# icont5_cfg_targetdb register map
Vendor: Texas Instruments
Peripheral module from a debugger description file (folder iva2_arp32).
Address unit: 16 bits
Registers are 32-bit, read-write, reset 0x0 unless marked. A register's access mark holds for its fields unless they carry their own. Offsets are as the file gives them; lines under a group give offsets from that group; [hi:lo] are bit positions; {n}, {i} and the like mark numbered series; 'fields as' and 'values as' point back to an identical list; <NAME> marks a mode.

## DSS — ipxact12_to_ccs_generated
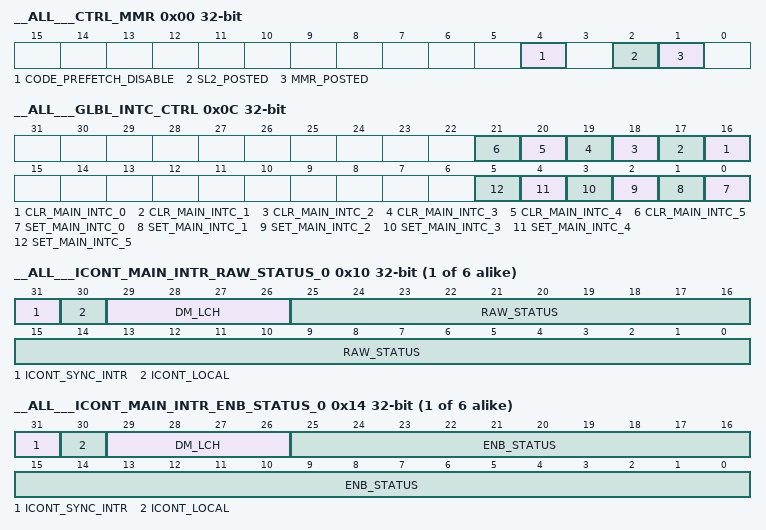
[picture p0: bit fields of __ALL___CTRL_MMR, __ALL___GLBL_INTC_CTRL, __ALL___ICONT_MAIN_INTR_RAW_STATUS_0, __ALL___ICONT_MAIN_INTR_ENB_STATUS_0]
0x00 __ALL___CTRL_MMR access per field
  [4] CODE_PREFETCH_DISABLE rw — Disable code prefetch from SL2 space.
  [2] SL2_POSTED rw — When set, SL2 posted writes from CPU will be enabled. When cleared, all SL2 writes from CPU are performed as non-posted writes (Write Queue will be disabled after completing the pending writes).
  [1] MMR_POSTED rw — When set, Posted MMR writes from CPU will be enabled. When cleared, all MMR writes from CPU are performed as non-posted writes.
0x0C __ALL___GLBL_INTC_CTRL — Global Interrupt controller enable register.
  [n+16] CLR_MAIN_INTC_{n} (n=0..5) — Write 1 to disable Main_{n} Interrupt controller.
  [n] SET_MAIN_INTC_{n} (n=0..5) — Write 1 to enable Main_{n} Interrupt controller. Read returns the Interrupt controllers enabled/disabled state.
{0x10+0x20*i} __ALL___ICONT_MAIN_INTR_RAW_STATUS_{i} access per field (i=0..5) — This provides the status of the ICONT Main interrupt sources, irrespective of enable bit. Write 1 to set the interrupt in Software (for test/debug).
  [31] ICONT_SYNC_INTR ro — ICONT Sync interrupt Source
  [30] ICONT_LOCAL ro — ICONT Local Interrupt Controller interrupt.
  [29:26] DM_LCH rw — Data Mover Logical Channel Data Transfer completion.
  [25:0] RAW_STATUS rw
{0x14+0x20*i} __ALL___ICONT_MAIN_INTR_ENB_STATUS_{i} access per field (i=0..5) — This provides the status of the ICONT Main interrupt sources enabled to interrupt. Write 1 to clear the interrupt in Software.
  [31] ICONT_SYNC_INTR ro — ICONT Sync interrupt Source
  [30] ICONT_LOCAL ro — ICONT Local Interrupt Controller interrupt.
  [29:26] DM_LCH rw — Data Mover Logical Channel Data Transfer completion.
  [25:0] ENB_STATUS rw
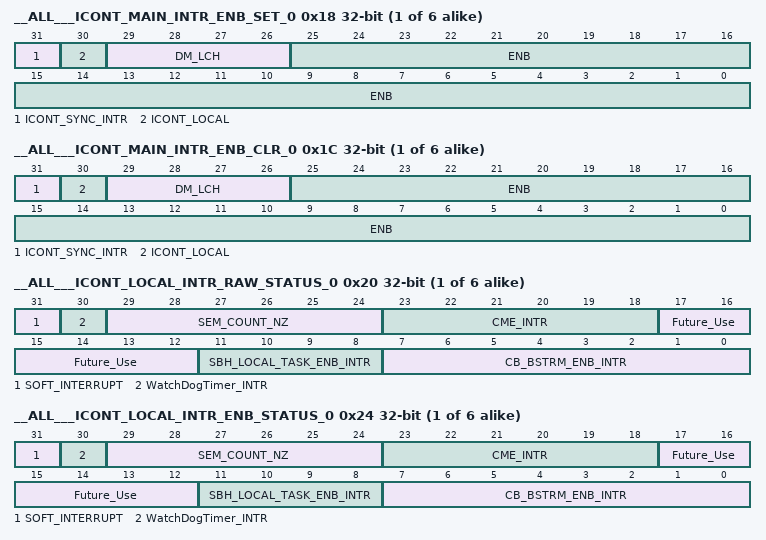
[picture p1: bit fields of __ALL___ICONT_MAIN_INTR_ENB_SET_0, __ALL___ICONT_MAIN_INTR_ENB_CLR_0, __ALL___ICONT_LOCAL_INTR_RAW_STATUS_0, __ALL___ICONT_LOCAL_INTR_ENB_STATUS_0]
{0x18+0x20*i} __ALL___ICONT_MAIN_INTR_ENB_SET_{i} (i=0..5) — Enables the corresponding interrupt source to generate interrupt. Write 1 to set the corresponding interrupt enable bit.
  [31] ICONT_SYNC_INTR — ICONT Sync interrupt Source
  [30] ICONT_LOCAL — ICONT Local Interrupt Controller interrupt.
  [29:26] DM_LCH — Data Mover Logical Channel Data Transfer completion.
  [25:0] ENB
{0x1C+0x20*i} __ALL___ICONT_MAIN_INTR_ENB_CLR_{i} (i=0..5) — Enables the corresponding interrupt source to generate interrupt. Write 1 to Clear the corresponding interrupt enable bit.
  fields as __ALL___ICONT_MAIN_INTR_ENB_SET_0
{0x20+0x20*i} __ALL___ICONT_LOCAL_INTR_RAW_STATUS_{i} (i=0..5) — This provides the status of the ICONT internal interrupt sources, irrespective of enable bit. Write 1 to set the interrupt in Software (for test/debug).
  [31] SOFT_INTERRUPT — Software Interrupt Source.
  [30] WatchDogTimer_INTR — WatchDog Timer interrupt.
  [29:24] SEM_COUNT_NZ — Interrupt source from the Semaphore counter. Refer Semaphore counter section for more details.
  [23:18] CME_INTR — CME Counter non-zero interrupt.
  [17:12] Future_Use — Reserved for Future use. Refer SL2BC section for more details.
  [11:8] SBH_LOCAL_TASK_ENB_INTR — Local SBH Task Notification
  [7:0] CB_BSTRM_ENB_INTR — BitStream Custom Block Interrupt Sources. 0 : Page_Done 1 : UnderRun 2 : Start_Code 3 : Store_Complete. 4 : Thress_Cross 5 : DDR_Empty 6 : Active to InActive transition. 7 : Start_Code_Overrun Refer Custom Block Bitstream section for details on its assertion & clearing.
{0x24+0x20*i} __ALL___ICONT_LOCAL_INTR_ENB_STATUS_{i} (i=0..5) — This provides the status of the ICONT internal interrupt sources enabled to interrupt. Write 1 to clear the interrupt in Software.
  fields as __ALL___ICONT_LOCAL_INTR_RAW_STATUS_0
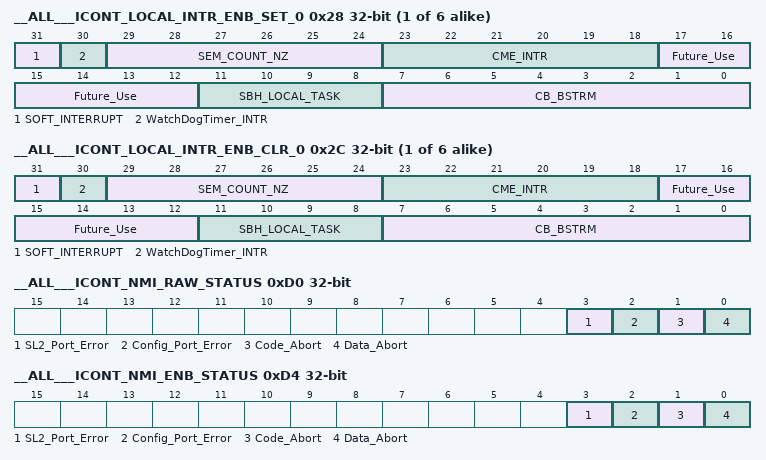
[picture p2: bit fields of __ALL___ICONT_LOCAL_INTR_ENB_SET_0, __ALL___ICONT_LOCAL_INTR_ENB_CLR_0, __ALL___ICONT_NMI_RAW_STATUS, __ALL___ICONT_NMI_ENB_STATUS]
{0x28+0x20*i} __ALL___ICONT_LOCAL_INTR_ENB_SET_{i} (i=0..5) — Enables the corresponding interrupt source to generate interrupt. Write 1 to set the corresponding interrupt enable bit.
  [31] SOFT_INTERRUPT — Enable Software Interrupt Source..
  [30] WatchDogTimer_INTR — WatchDog Timer interrupt.
  [29:24] SEM_COUNT_NZ — Interrupt source from the Semaphore counter.
  [23:18] CME_INTR — CME Counter non-zero interrupt.
  [17:12] Future_Use — Reserved for Future use. Refer SL2BC section for more details.
  [11:8] SBH_LOCAL_TASK — Enable Local SBH Task Notification.
  [7:0] CB_BSTRM — Enable BitStream Custom Block Interrupt Sources. 0 : Page_Done 1 : UnderRun 2 : Start_Code 3 : Store_Complete. 4 : Thress_Cross 5 : DDR_Empty 6 : Active to InActive transition. 7 : Start_Code_Overrun
{0x2C+0x20*i} __ALL___ICONT_LOCAL_INTR_ENB_CLR_{i} (i=0..5) — Enables the corresponding interrupt source to generate interrupt. Write 1 to Clear the corresponding interrupt enable bit.
  fields as __ALL___ICONT_LOCAL_INTR_ENB_SET_0
0xD0 __ALL___ICONT_NMI_RAW_STATUS access per field — This provides the status of the ICONT NMI sources, irrespective of enable bit. Write 1 to set the interrupt in Software (for test/debug).
  [3] SL2_Port_Error rw — Indicates error response on SL2 port.
  [2] Config_Port_Error rw — Indicates error response on Config master port.
  [1] Code_Abort rw — CPU Code access to Reserved space. NRP control register logs the access address.
  [0] Data_Abort rw — CPU data access to Reserved space. ICONT_NMI_ABORT_ADDR logs the access address.
0xD4 __ALL___ICONT_NMI_ENB_STATUS access per field — This provides the status of the ICONT NMI interrupt sources enabled to interrupt. Write 1 to clear the interrupt in Software.
  [3] SL2_Port_Error rw — Indicates error response on SL2 port.
  [2] Config_Port_Error rw — Indicates error response on Config master port.
  [1] Code_Abort rw — CPU code access to Reserved space. NRP control register logs the access address.
  [0] Data_Abort rw — CPU data access to Reserved space. ICONT_NMI_ABORT_ADDR logs the access address.
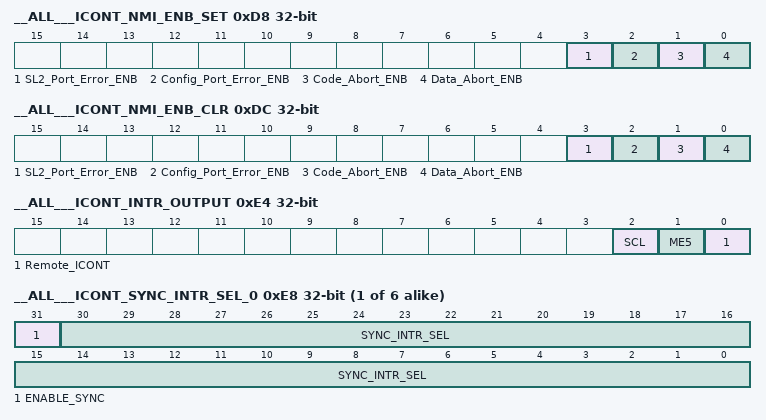
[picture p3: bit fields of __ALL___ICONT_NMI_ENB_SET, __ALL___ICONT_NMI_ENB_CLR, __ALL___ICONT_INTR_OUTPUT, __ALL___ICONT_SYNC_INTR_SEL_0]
0xD8 __ALL___ICONT_NMI_ENB_SET access per field — Enables the corresponding interrupt source to generate interrupt. Write 1 to set the corresponding interrupt enable bit.
  [3] SL2_Port_Error_ENB rw, [2] Config_Port_Error_ENB rw, [1] Code_Abort_ENB rw, [0] Data_Abort_ENB rw
0xDC __ALL___ICONT_NMI_ENB_CLR access per field — Enables the corresponding interrupt source to generate interrupt. Write 1 to Clear the corresponding interrupt enable bit.
  fields as __ALL___ICONT_NMI_ENB_SET
0xE0 __ALL___ICONT_NMI_ABORT_ADDR ro — Logs the Address that resulted in the CPU Data abort condition.
  [31:0] Address
0xE4 __ALL___ICONT_INTR_OUTPUT — Generates interrupt to remote ICONT, ME5, SCL modules. Corresponding bitfield is to be set to generate interrupt. The bitfield is selfcleared on generating interrupt.
  [2] SCL — Generates Interrupt to Scalar.
  [1] ME5 — Generates Interrupt to ME5.
  [0] Remote_ICONT — reserved.
{0xE8+4i} __ALL___ICONT_SYNC_INTR_SEL_{i} (i=0..5) — Selects the interrupt sources to be considered to generate the SYNC interrupt source
  [31] ENABLE_SYNC — When cleared to 0, blocks the SYNC interrupt generation. When set to 1, enables the SYNC interrupt to be generated.
  [30:0] SYNC_INTR_SEL
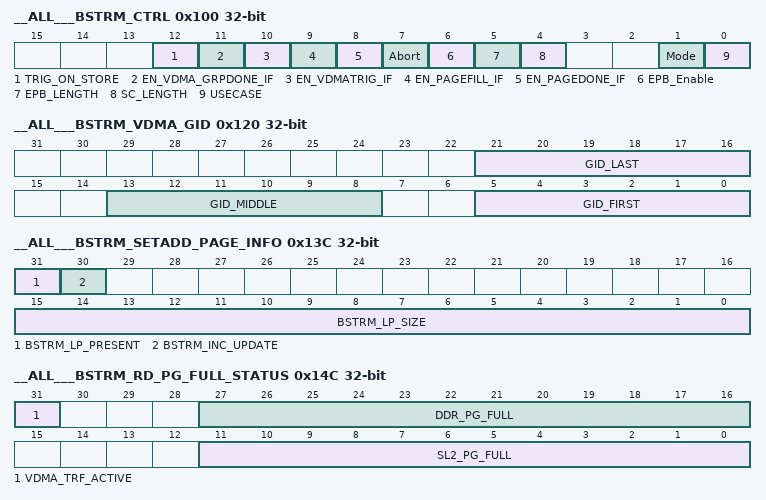
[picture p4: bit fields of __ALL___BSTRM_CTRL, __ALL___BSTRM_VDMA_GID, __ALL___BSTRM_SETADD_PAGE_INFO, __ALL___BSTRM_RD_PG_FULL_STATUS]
0x100 __ALL___BSTRM_CTRL access per field — This register is written by Software as part of configuration.
  [12] TRIG_ON_STORE rw — This is used in Encode usecase to specify if the BSTRM_STORE() CI should be considered as end of page, even when not completely filled. When 1, The BSTRM_STORE() CI should trigger all events that simillar to page fill on the last SL2 write. When 0, trigger is not generated on SL2 write completion.
  [11] EN_VDMA_GRPDONE_IF rw — Enables (when high) the VDMA to ICONT interface to communicate Page_Fill status. This should be enabled in Encode & in Slice level pipelining decode flow.
  [10] EN_VDMATRIG_IF rw — Enables (when high) the ICONT to VDMA Group Start trigger interface to communicate Page_Done status. This should be enabled in Encode & in Slice level pipelining decode flow.
  [9] EN_PAGEFILL_IF rw — Enables (when high) the ECD to ICONT interface to communicate Page_Fill status. This should be enabled in Sequential decode/encode flow.
  [8] EN_PAGEDONE_IF rw — Enables (when high) the ICONT to ECD interface to communicate Page_Done status. This should be enabled in Sequential decode/encode flow.
  [7] Abort rw — When asserted by software, forces the hardware to move to IDLE state (after completing the ongoing transfer). Writing 0 to this bit is ignored. This bit is auto cleared by HW.
  [6] EPB_Enable rw — Enables EPB byte detection & removal by hardware in Decoder Usecase. Enables EPB byte insertion by hardware in Encoder Usecase.
  [5] EPB_LENGTH rw — Specifies the length of the EPB pattern. 0 implies 3 Bytes pattern (lower bytes). 1 implies 4 Byte pattern.
  [4] SC_LENGTH rw — Specifies the length of the StartCode pattern. 0 implies 3 Bytes pattern (lower bytes). 1 implies 4 Byte pattern.
  [1] Mode rw — Used in Decoder usecase only. When set to 0, implies Typical flow where BitStream custom block and ECD HW block is used in sequential mode. When set to 1, implies Slice Level Pipeline mode where in BitStream custom block is used in parallel with ECD HW block.
  [0] USECASE rw — Indicates how the BitStream Custom Unit is being used. 0 indicates Decode usecase (default). 1 indicates Encode Usecase.
0x104 __ALL___BSTRM_SC_VAL reset 0x1 — This register is written by Software as part of configuration. This specifies the 32bit value that will be used as StartCode by Custom Unit.
  [31:0] SC_VAL — Start Code Pattern
0x108 __ALL___BSTRM_EPB_VAL reset 0x3 — This register is written by Software as part of configuration. In Decoder usecase, this specifies the 32 bit value that is detected as the Emulation Prevention Byte. The unit could be configured to automatically remove the least significant byte from the BitStream on detection. In Encoder usecase, this specifies the 32 bit value that is used along with BSTRM_EPB_MASK to detect when the EmulationPreventionByte is to be inserted. The unit could be configured to automatically insert the least significant byte of this register to the BitStream when needed.
  [31:0] EPB_VAL — For example, in Case of H-264 byte oriented stream, this value should be set to 0x000003.
0x10C __ALL___BSTRM_EPB_MASK reset 0xFFFFFFFC — This register is written by Software as part of configuration in Encoder usecase. This specifies the 32 bit mask value that will be used along with BSTRM_EPB_VAL in identifying Emulation Prevention Byte insertion.
  [31:0] EPB_MASK — Each bitfield enables the corresponding bitfield of BSTRM_EPB_VAL in Encoder usecase. For example, in Case of H-264 byte oriented stream, this value should be set to 0x00FFFFFC to detect 0x000001 and 0x000003 as condition needing EPB byte insertion.
0x110 __ALL___BSTRM_PAGE_SA — This register is written by Software as part of configuration. This specifies the starting address of the circular buffer in SL2 and is used to wrap around.
  [31:0] Start_Address — Starting address of the circular buffer. Address should be 128bit aligned and also aligned to the page size specified in BSTRM_PAGE_SIZE.
0x114 __ALL___BSTRM_PAGE_SIZE access per field — This register is written by Software as part of configuration. This specifies the size of each page in SL2. The value written is expected to be a one-hot value indicating the size in bytes. (For ex: 512Bytes = 0x200)
  [15:0] Page_Size rw — The value written is expected to be a one-hot value indicating the size in bytes. (For ex: 512Bytes = 0x200) Minimum supported size of page is 128bytes.
0x118 __ALL___BSTRM_PAGE_NUM access per field — This register is written by Software as part of configuration. This specifies the number of pages contained in the circular buffer.
  [15:0] Page_Num rw — Number of pages in the circular buffer
0x11C __ALL___BSTRM_THRESHOLD access per field — This is used in Decoder & Encoder usecase. In Decoder, This specifies the low watermark limit of the Valid data in SL2 buffer, below which the THRES_CROSS status bit need to be asserted by Custom Block. The contents of checked in the following sequence, work buffer, pre-fetch buffer, SL2 buffer. Note in case the EPB removal is enabled, the custom block would not know the EPB bytes in the portion that are in SL2. So, care is to be taken to account for this while programming this register. The value configured in this register should not exceed the page size. In Encode usecase, This specifies the low watermark limit of the free space in SL2 buffer, below which the THRES_CROSS status bit need to be asserted by Custom Block. Note in case the EPB removal is enabled, SW should include margin for EPB insertion while programming this register.
  [15:0] THRESHOLD rw — Decode usecase : Specifies the low-water mark of Valid Data in SL2 in terms of bytes. Encode usecase : Specifies the low-water mark of Free Space in SL2 in terms of bytes. This value should not exceed Page Size.
0x120 __ALL___BSTRM_VDMA_GID — Used when VDMA HW interface is enabled. This specifies the VDMA Group ID that should be used to trigger the VDMA transfers and to monitor the VDMA GroupDone.
  [21:16] GID_LAST — This VDMA GID is used when triggering the VDMA for the last page in Decode mode. Last page is assumed when BSTRM_LP_PRESENT bitfield is set to 1 and triggering for the last DDR PAGE. Not used in Encode usecase.
  [13:8] GID_MIDDLE — This VDMA GID is used when triggering the VDMA for the all pages except the first & last in Decoder mode. In Encode mode, This GID is used for all vdma transfers.
  [5:0] GID_FIRST — This VDMA GID is used when triggering the VDMA for the first page when _BSTRM_CONF CI is issued (with SL2 Filled Pages being 0*) in Decode mode. This value could be same as that of VDMA_GID_MIDDLE when the first page to be fetched is a full page. It could have a different GID value when the first page in DDR is partial and need to be bottom aligned in SL2 page. Note:* This GID will not be used if DDR page count equals 1 and Last Page is indicated. In this case, The first VDMA transfer will be triggerred with the GID_LAST ID. Not used in Encode usecase.
0x124 __ALL___BSTRM_SET_ADDR — Specifies the starting address (byte address) of the new BitStream in the SL2 page.
  [31:0] SET_ADDR
0x134 __ALL___BSTRM_SETADD_SL2_PG_FULL wo — BSTRM_SET_SL2_PG_FULL: (When Active bitfield in BSTRM_STAUS register is 0) In Decoder usecase in Typical flow (mode=0). Specifies the number of SL2 pages filled with BitStream data at the start of processing. In Encoder usecase, This specifies the number of SL2 pages that are empty at the start of processing. BSTRM_ADD_SL2_PG_FULL: (When Active bitfield in BSTRM_STAUS register is 1) In Decoder usecase, the subsequent SL2 page fills could be conveyed through SW by writing the incremental SL2 pages filled value. Note: This approach is used when HW interface is not used (ie., EN_VDMA_GRPDONE & EN_PAGEDONE bitfields are set to 0). In Encode usecase, Subsequent SL2 page availablity could be conveyed by SW by writing the incremental SL2 page value. Note: In both usecase, when used to convey incremental value, the HW will take the updated value when BSTRM_INC_UPDATE bitfield is set to 1.
  [11:0] SL2_PAGES — Specifies the amount of BitStream data available in DDR in terms of SL2 pages. All writes, done after initiating the BitStream custom unit, with non-zero value will be considered as additional page available. Used to generate VDMA triggers to fetch the data from DDR to SL2 when HW interface is enabled.
0x138 __ALL___BSTRM_SETADD_DDR_PAGES wo — Used in Decoder & Encoder usecase. BSTRM_SET_DDR_PAGES: (When Active bitfield in BSTRM_STATUS register is 0) This register is used to convey information related to BitStream Data in DDR that is yet to be copied to SL2 at the start of processing in Decoder usecase. This register is used to convey information related to pages available in DDR to store the encoded bitstream data in Encoder usecase. BSTRM_ADD_DDR_PAGES: (When Active bitfield in BSTRM_STATUS register is 1) When additional data is available in DDR after initiation in Decoder Fixed Chunk format (refer programming model section for details on Fixed Chunk format) or in encode usecase, the provided value is used to increment the earlier value. Note: When used to convey incremental value, the HW will take the updated value when BSTRM_INC_UPDATE bitfield is set to 1.
  [11:0] BSTRM_SETADD_DDR_PAGES — This is used in when HW interface is enabled to i) generate triggers on the VDMA HW interface (when enabled) on PageDone indication. ii) Determine if the current SL2 page is the last page (when Last_pg_present is set).
0x13C __ALL___BSTRM_SETADD_PAGE_INFO access per field — This is used to convey information regarding LastPage and its Size.
  [31] BSTRM_LP_PRESENT wo — This field is used in Decoder usecase only. This field indicates if the Last Page is present in SL2 or in DDR(When HW interface is used). This is always set in Frame or N-Nal format. In case of Fixed Chunk format, this depends on the BitStream data (refer Programming Model section for details on formats). This field is updated along with BSTRM_ADD_DDR_PAGES in Fixed Chunk format.
  [30] BSTRM_INC_UPDATE rw — This bitfield is used in both decode and encode usecase. This BSTRM_INC_UPDATE bitfield needs to be set to 1 to enable the Bitstream custom block to use the incremental value written in the following registers. 1) BSTRM_ADD_SL2_PG_FULL 2) BSTRM_ADD_DDR_PAGES 3) BSTRM_LP_SIZE 4) BSTRM_LP_PRESENT The BSTRM_INC_UPDATE bit will be autocleared to 0 on HW register update. After the HW registers are updated, BSTRM_SETADD_SL2_PG_FULL & BSTRM_SETADD_DDR_PAGES MMRs will be reset to zero (to ease subsequent incremental writes).
  [15:0] BSTRM_LP_SIZE rw — This field is used in Decoder usecase only. This specifies the size of the last page (in SL2). This register is written by Software as part of setup (using BSTRM_CONF() CI) or while updating when additional data chunks are available (SW update by setting BSTRM_INC_UPDATE=1). The value written is expected to be in terms of bytes. Note that the data need not be available in SL2 at the time of updating this register. When BSTRM_LP_PRESENT was already asserted during the previous update (either during setup or during incremental update), the new BSTRM_LP_SIZE value adds to the previous specified value.
0x140 __ALL___BSTRM_RD_ADDR ro — Returns the SL2 address pointing to the next bitstream data to be processed in Decoder usecase. Returns the SL2 address where the next bitstream byte is to be written in Encoder usecase. Note: Also refer LATCH_STATUS bit description.
  [31:0] RD_ADDR — SL2 address being processed in Decoder usecase. SL2 address to be written in Encoder usecase. Note that the BSTRM_RD_ADDR will not change after UNDERRUN/OVERFLOW status is set.
0x144 __ALL___BSTRM_RD_BITPTR ro — Returns the Bit pointer to be processed in Decoder usecase. Returns the current Bit Pointer within the Bitstream being encoded in encoder usecase. Note: Also refer LATCH_STATUS bit description.
  [2:0] RD_BitPtr — Note that the BSTRM_RD_BITPTR will not change after UNDERRUN/OVERFLOW status is set. Decoder usecase: Follows Big Endian notation. 0=>all 8 bits valid. Next bit to be read starting from bit[7] 1=>7 bits valid in byte starting from bit[6]. ... 7=>only 1 bit valid in the byte at position[0] Encoder usecase: 0=>Byte aligned. Next bit to be written at bit[7]. 1=>1bit present. Next bit to be written at bit[6]. ... 7=>7bits present. Next bit to be written at bit[0].
0x148 __ALL___BSTRM_RD_ZERO_BYTE_CNT ro — In decoder usecase: This register provides the count of zero bytes seen at the current Byte pointer. In Encoder usecase: This register provides the count of zero bytes encoded at the current byte pointer. Note: Also refer LATCH_STATUS bit description.
  [1:0] Zero_Byte_Count — Count of Zero bytes decoded/encoded at the current byte position. 0 : Byte pointer at end of non-zero byte position. 1 : Byte pointer has seen/encoded one zero-byte. 2 : Byte pointer has seen/encoded two zero-byte. 3 : Byte pointer has seen/encoded three or more zero-byte/s. Note: The contents of this register during Search of SC pattern or Non-Zero byte pattern (_BSTRM_Search_Bits CI) would be 1) Zero when the search ends sucessfully by detecting the pattern. 2) undefined when the search is aborted by SW or ends in an underrun condition.
0x14C __ALL___BSTRM_RD_PG_FULL_STATUS ro — In Decoder usecase. Returns the count of SL2 & DDR pages that contains BitStream data. (The count update of SL2 & DDR pages happens on the same cycle, thereby ensuring correct counts on all reads). In Encoder usecase. Returns the count of SL2 pages that are still empty. Note: Also refer LATCH_STATUS bit description.
  [31] VDMA_TRF_ACTIVE — Status bit indicating VDMA transfer trigerred by custom block (when VDMA hw interface is enabled) is ongoing.
  [27:16] DDR_PG_FULL — Used in SLice level Pipelining Flow only. Returns the count of DDR pages that contains (unread) BitStream data.
  [11:0] SL2_PG_FULL — Returns the count of SL2 pages that contains BitStream data (including the page being processed).
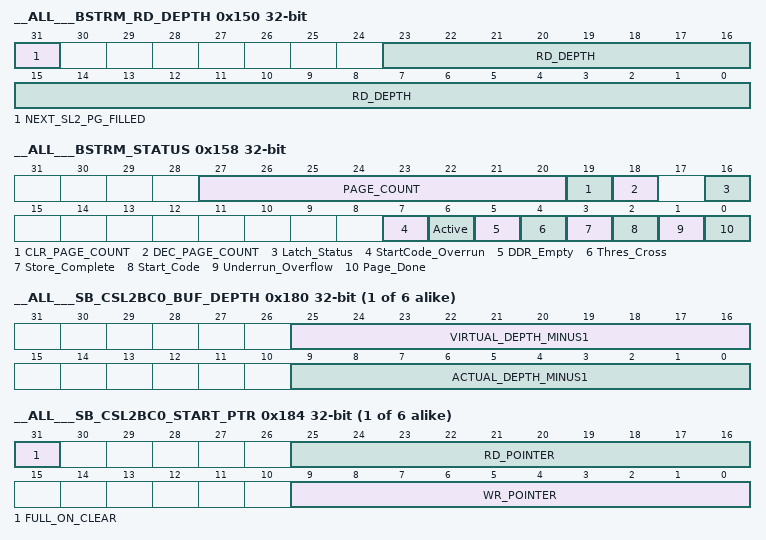
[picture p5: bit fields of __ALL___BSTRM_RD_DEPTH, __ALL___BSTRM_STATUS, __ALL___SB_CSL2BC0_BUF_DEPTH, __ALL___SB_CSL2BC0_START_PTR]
0x150 __ALL___BSTRM_RD_DEPTH ro — Returns the bytes yet to be read in the allocated SL2 pages in Decoder usecase. Returns the bytes yet to be filled in the allocated SL2 pages in Encoder usecase. (return value is ceiled to BSTRM_PAGE_SIZE) Note: Also refer LATCH_STATUS bit description.
  [31] NEXT_SL2_PG_FILLED — Decoder usecase: Indicates if the next SL2 page is filled with unread BitStream data (High) or is empty (Low=to be filled) Encoder usecase: Indicates if the more than 1 page is available for writing (when 1) or just one or no page is available(when 0).
  [23:0] RD_DEPTH — Returns the byte count. (Ceiled to BSTRM_PAGE_SIZE)
0x158 __ALL___BSTRM_STATUS access per field — Provides status of the custom block. Software writes 1 to the corresponding bitfield (except Thres_Cross & Active) to clear the events.
  [27:20] PAGE_COUNT ro — This bitfield is used in both Decode and Encode usecase. This bitfield is used in systems where the interrupt latency exceeds the custom block page processing time. When HW interface (either ECD or VDMA) is not enabled, this bitfield will be incremented by Custom Block on every page freed(in decode)/filled(in encode). SW would acknowledge this by decrementing (recommended) or clearing this bitfield. When VDMA HW interface is enabled, this bitfield is incremented on page freed/filled event that did not generate in VDMA trigger. This is possible when the VDMA is actively transferring data of last trigger or when the provided DDR_PAGES count has reached 0. For the former case, the custom block will decement this count when it triggers the next VDMA transfer. For latter, SW could either provide additional DDR pages to custom block OR could acknowledge its handling of "extra" page transfers by decrementing the count. This bitfield is not used when ECD HW interface is enabled. SW should update the PAGE_COUNT bitfield by writing 1 to the DEC_PAGE_COUNT or CLR_PAGE_COUNT bitfields. Writing 1 to DEC_PAGE_COUNT will decrement the PAGE_COUNT content by 1. Writing 1 to CLR_PAGE_COUNT will clear the PAGE_COUNT contents.
  [19] CLR_PAGE_COUNT rw — SW writes 1 to this bitfiles to clear the PAGE_COUNT bitfield to 0. This bit is auto cleared. (Note: The value will be updated in next cycle)
  [18] DEC_PAGE_COUNT rw — SW writes 1 to this bitfiles to decrement the PAGE_COUNT bitfield by 1. This bit is auto cleared. (Note: The value will be updated in next cycle)
  [16] Latch_Status rw — Used in both Encode & Decode Usecase. This bit has to be set to 1 to copy the current HW status registers into the memory mapped registers. This bit will be auto cleared to 0. Note: HW will implicitly assume Latch_Status condition when the Bitstream makes transition from ACTIVE to IDLE state. (ie., During Abort condition in Decoder usecase or Store_Complete condition in encode usecase). The following memory mapped register contents will be updated when this bit is set to 1. 1) BSTRM_RD_ADDR 2) BSTRM_RD_BITPTR 3) BSTRM_RD_ZERO_BYTE_CNT 4) BSTRM_RD_PG_FULL_STATUS 5) BSTRM_RD_PAGE_STATUS2 6) BSTRM_RD_DEPTH The above register will hold its contents untill LATCH_STATUS is set to 1 again.
  [7] StartCode_Overrun rw — This is used in Decoder usecase. This is asserted when StartCode is "parsed" as data using _BSTRM_READ*/FLUSH CIs. This bit is cleared by writing 1 to this bit.
  [6] Active ro — This indicates if the BitStream Custom Block is in active state (1) or in idle state (0). This bit is set by the _BSTRM_Conf intrinsic in both encode and decode usecase. This bit is cleared on the following condition i) Abort bitfield is set in BSTRM_CTRL register and on completion of active SL2 transaction. ii) _BSTRM_Store intrinsic is issued in encode usecase and on completing all SL2 writes. (will wait for VDMA completion as well) Note: Active bit is not cleared on underrun or overflow error. This is a readonly bit.
  [5] DDR_Empty rw — This bit is used only in Decode usecase, is set when the configured number of transfers (see BSTRM_SETADD_DDR_PAGES register) is completed. SW can use this to update the VDMA descriptor with the next portion of Bitstream is located at different DDR address. Along with the VDMA descriptor, SW should indicate the additional DDR page count and the page information by updating the BSTRM_SETADD_DDR_PAGES and BSTRM_SET_PAGE_INFO accordingly. This bit is cleared by writing 1 to this bit.
  [4] Thres_Cross ro — This bit in Decode usecase: This status bit is set when the number of unread bytes within Custom Block (after EPB removal) plus the unread bytes in SL2 is less than the value configured in BSTRM_THRESHOLD register. This bit gets cleared when additional data is added in SL2. This bit in Encode usecase: This status bit is set when the number of free bytes in SL2 is less than the value configured in BSTRM_THRESHOLD register. This bit gets cleared when additional SL2 pages are freed(gets written to DDR). This bit is auto cleared by HW when the condition to set is no longer present.
  [3] Store_Complete rw — This bit is used in Encode usecase. This is asserted by custom unit subsequent to _BSTRM_Store instruction, when the encoded BitStream present in work buffer or prefetch buffer are written in SL2. When VDMA trigger is enabled, this assertion waits for VDMA transfer completion. This bit is cleared by writing 1 to this bit.
  [2] Start_Code rw — This bit is used in decode usecase. This is asserted by custom block, when initiated to detect the start code in BitStream data, on detecting the start_code. This is asserted by custom block, when initiated without start code detection, when the work buffer is filled with prefetch data. This bit is cleared by writing 1 to this bit.
  [1] Underrun_Overflow rw — This is used in both decoder & encoder usecase. Note that the BSTRM_RD_BITPTR and BSTRM_RD_ADDR will not change after UNDERRUN/OVERFLOW status is set. This UNDERRUN bit is set in two conditions in Decoder usecase 1) During BitStream SW parsing when it exhausts all the valid data in SL2. 2) During StartCode search, when it does not find the StartCode and exhausts all valid data provided with LP_Present =1. This bit is cleared by writing 1 to this bit. This OVERFLOW bit is set in two conditions in encoder usecase 1) During BitStream SW encoding when all the CB buffers and SL2 pages are filled. This bit is cleared by writing 1 to this bit.
  [0] Page_Done ro — This bit is used in both Decode and Encode usecase, when HW interface is not enabled. In Decode usecase, this bit is set when the custom block parsing crosses a page. In Encode usecase, this bit is set when the custom block store writes to the last location of the page. Note that page_done set condition will also increment the PAGE_COUNT bitfield of this register. SW should update the PAGE_COUNT bitfield by writing 1 to the DEC_PAGE_COUNT (recommended) or CLR_PAGE_COUNT(when no further page_done set condition is expected) bitfields. This Page_Done bit gets cleared by HW when PAGE_COUNT bitfield contents equals zero.
0x15C __ALL___BSTRM_RD_PAGE_STATUS2 ro — In Decoder usecase. Returns the count of SL2 & DDR pages that contains BitStream data. (The count update of SL2 & DDR pages happens on the same cycle, thereby ensuring correct counts on all reads). In Encoder usecase. Returns the count of SL2 pages that are still empty. Note: Also refer LATCH_STATUS bit description.
  [15:0] CONSUME_PAGE — Returns the cumulative count of SL2/DDR page consumed(decode)/filled(encode) by the Custom Block. This bitfield is cleared when BSTRM_Config CI is issued.
{0x180+0xC*i} __ALL___SB_CSL2BC{i}_BUF_DEPTH access per field (i=0..5) — Buffer depth configuration register for Consumer SL2BC{i}.
  [25:16] VIRTUAL_DEPTH_MINUS1 rw — Indicates the Maximum pointer difference. Virtual buffer depth < Actual buffer depth. When the pointer difference is more than the virtual buffer depth the wr_bc_ready gets de-asserted. For Normal use cases, virtual depth = actual depth. For H241 rewind, virtual depth < actual depth. The difference between the actual and virtual depth indicates the number of MB’s by which the buffer can be rewinded.
  [9:0] ACTUAL_DEPTH_MINUS1 rw — Number of entries in the Buffer = 1 + Actual_ depth_minus1
{0x184+0xC*i} __ALL___SB_CSL2BC{i}_START_PTR access per field (i=0..5) — Configures the Initial value of Buffer pointers for Consumer SL2BC{i}.
  [31] FULL_ON_CLEAR rw — If start value of RD pointer = start value of WR pointer as configured in the BUF_START_PTR then 0: Buffer is empty on BC_CLR 1: Buffer is full on BC_CLR
  [25:16] RD_POINTER rw — Start value of Read pointer, initialized on BC_CLR. Range: 0 to Actual_depth_minus1
  [9:0] WR_POINTER rw — Start value of Write pointer, initialized on BC_CLR. Range: 0 to Actual_depth_minus1
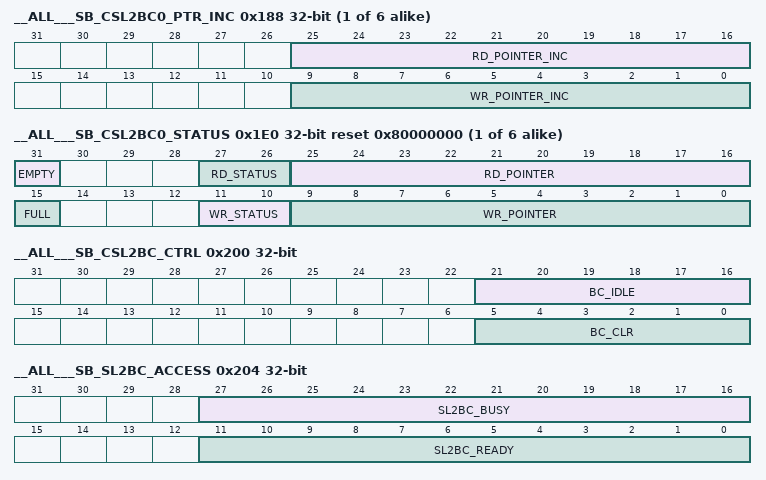
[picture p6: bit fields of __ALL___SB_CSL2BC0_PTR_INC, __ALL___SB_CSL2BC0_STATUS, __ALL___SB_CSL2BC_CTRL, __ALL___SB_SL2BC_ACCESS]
{0x188+0xC*i} __ALL___SB_CSL2BC{i}_PTR_INC access per field (i=0..5) — Configures the increment offset for buffer pointers of Consumer SL2BC{i}.
  [25:16] RD_POINTER_INC rw — Increment value for read pointer on rd_core_busy deassertion. Range: 0 to Actual_depth_minus1+1
  [9:0] WR_POINTER_INC rw — Increment value for write pointer on wr_core_busy deassertion. Range: 0 to Actual_depth_minus1+1
{0x1E0+4i} __ALL___SB_CSL2BC{i}_STATUS ro reset 0x80000000 (i=0..5) — Indicates Status of Consumer SL2BC{i}.
  [31] EMPTY — buffer empty status ‘1’ -> buffer is empty ‘0’ -> buffer is not empty
  [27:26] RD_STATUS — Indicates the BC status on the read side BC NOT READY = 00 (rd_core_busy=0 & rd_bc_ready=0) BC READY = 01 (rd_core_busy=0 & rd_bc_ready=1) BC BUSY = 1x (rd_core_busy=1)
  [25:16] RD_POINTER — Current Read pointer value which is going to be read or being read. Read pointer will always be less than ‘Actual buffer depth ’
  [15] FULL — buffer full status ‘1’ -> buffer is full ‘0’ -> buffer is not full
  [11:10] WR_STATUS — Indicates the BC status on the write side BC NOT READY = 00 (wr_core_busy=0 & wr_bc_ready=0) BC READY = 01 (wr_core_busy=0 & wr_bc_ready=1) BC BUSY = 1x (wr_core_busy=1)
  [9:0] WR_POINTER — Current Write pointer value which is going to be written or which is being written. Write pointer will always be less than ‘Actual buffer depth ’
0x200 __ALL___SB_CSL2BC_CTRL access per field — This register allows assertion of BC_CLR and BC_IDLE of Consumer SL2BCs. When Sl2BC are used as part of the IVAHD message network, SW has to ensure the following: BC_CLR should be asserted after receiving the hwa_init_ack/resume_ack from all the HWA+MSG_NW_TOP. BC_IDLE should be asserted after pipedown/rewind_attn.
  [21:16] BC_IDLE rw — Disables the bc_ready generation. Bc_pointer is untouched. Bit Position: SL2BC ID 0 : CSL2BC0 1 : CSL2BC1 2 : CSL2BC2 3 : CSL2BC3 4 : CSL2BC4 5 : CSL2BC5
  [5:0] BC_CLR rw — Initializes the BC pointers to the configured values (as configured in the BUF_START_PTR MMR) and enable the bc_ready generation. BC_CLR should be set only when the BC is in IDLE State and all the other BC registers are programmed to avoid the undefined behaviour. Bit Position: SL2BC ID 0 : CSL2BC0 1 : CSL2BC1 2 : CSL2BC2 3 : CSL2BC3 4 : CSL2BC4 5 : CSL2BC5
0x204 __ALL___SB_SL2BC_ACCESS ro — This register provides CPU access to the current state of Ready and Busy signals of the ICONT Consumer & Producer SL2BC.
  [27:16] SL2BC_BUSY — Asserted (high) Busy indicates SW/SBH task consuming/generating the data, using SL2BC, is in progress. Bit Position: SL2BC name 0 : Busy of PSL2BC0 1 : Busy of PSL2BC1 2 : Busy of PSL2BC2 3 : Busy of PSL2BC3 4 : Busy of PSL2BC4 5 : Busy of PSL2BC5 6 : Busy of CSL2BC0 7 : Busy of CSL2BC1 8 : Busy of CSL2BC2 9 : Busy of CSL2BC3 10 : Busy of CSL2BC4 11 : Busy of CSL2BC5
  [11:0] SL2BC_READY — Provides the current state of the SL2BC Ready. (Read Only) 0 : Ready of PSL2BC0 1 : Ready of PSL2BC1 2 : Ready of PSL2BC2 3 : Ready of PSL2BC3 4 : Ready of PSL2BC4 5 : Ready of PSL2BC5 6 : Ready of CSL2BC0 7 : Ready of CSL2BC1 8 : Ready of CSL2BC2 9 : Ready of CSL2BC3 10 : Ready of CSL2BC4 11 : Ready of CSL2BC5
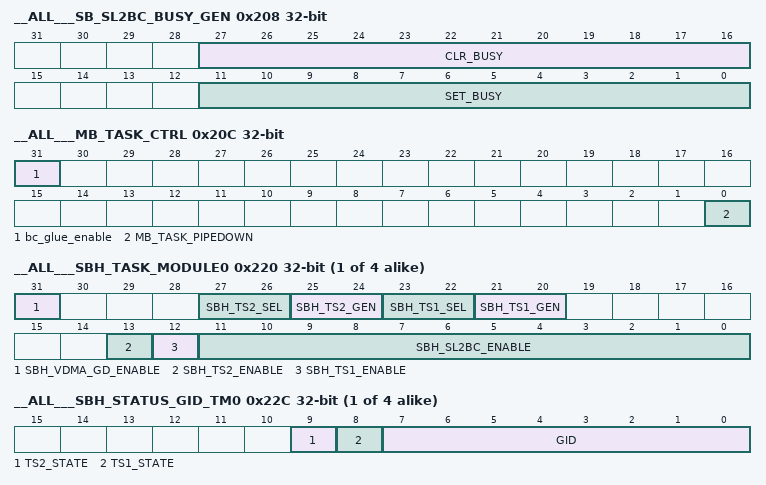
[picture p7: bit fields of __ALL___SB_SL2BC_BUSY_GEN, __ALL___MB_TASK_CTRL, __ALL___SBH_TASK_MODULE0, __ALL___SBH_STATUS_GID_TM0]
0x208 __ALL___SB_SL2BC_BUSY_GEN access per field — This register provides CPU access to the drive the Busy signals of the ICONT Consumer & Producer SL2BC. Assertion of Busy (by setting the bit to 1) indicates start of the SW task consuming/generating the data. De-assertion of Busy (by Clearing the bit to 0) indicates end of the SW task consuming/generating the data. Read of this register returns 0s. Note: Trying to SET and CLR the BUSY signal simultaneously will result in undefined behavior.
  [27:16] CLR_BUSY rw — De-assert the SL2BC BUSY signal by setting the corresponding bit to 1. Writing 0 has no effect. Bit Position: SL2BC name 0 : Busy of PSL2BC0 1 : Busy of PSL2BC1 2 : Busy of PSL2BC2 3 : Busy of PSL2BC3 4 : Busy of PSL2BC4 5 : Busy of PSL2BC5 6 : Busy of CSL2BC0 7 : Busy of CSL2BC1 8 : Busy of CSL2BC2 9 : Busy of CSL2BC3 10 : Busy of CSL2BC4 11 : Busy of CSL2BC5
  [11:0] SET_BUSY rw — Assert the SL2BC BUSY signal by setting the corresponding bit to 1. Writing 0 has no effect. 0 : Busy of PSL2BC0 1 : Busy of PSL2BC1 2 : Busy of PSL2BC2 3 : Busy of PSL2BC3 4 : Busy of PSL2BC4 5 : Busy of PSL2BC5 6 : Busy of CSL2BC0 7 : Busy of CSL2BC1 8 : Busy of CSL2BC2 9 : Busy of CSL2BC3 10 : Busy of CSL2BC4 11 : Busy of CSL2BC5
0x20C __ALL___MB_TASK_CTRL access per field — This register provides CPU access to the drive the EndOfPipe signal from ICONT during normal pipedown and error conditions. (Refer IVAHD toplevel flow doc for details) Read of this register returns 0s.
  [31] bc_glue_enable rw — Enables BC_Glue logic when set. SW sets the BC_GLUE_ENABLE bit during PipeUp, ResumePipe after setting the corresponding MMR bits in IVA_SYSCTRL. SW clears the BC_GLUE_ENABLE bit on PipeDown interrupt, Abort condition & Rewind Request interrupt.
  [0] MB_TASK_PIPEDOWN rw — RESERVED. NOT USED ANYMORE. EndOfPipe (po_pipedown) signal is asserted for one cycle when this register is set to 1. Auto clears to 0.
{0x220+0x10*i} __ALL___SBH_TASK_MODULE{i} (i=0..3) — This register configures the SBH Task Module {i}.
  [31] SBH_VDMA_GD_ENABLE — Enables the corresponding VDMA Group Done Monitor block to be used with the Task Module.
  [27:26] SBH_TS2_SEL — This bit configures the Task Start TS2 destination and selects the Task Completion TC2 source. When set to 00, enables TS2 to drive the Interrupt signal to CPU. It also selects SBH_SOFT_TC to be used as TC2. When set to 01, enables TS2 to drive the VDMA Group Start signal. It also selects SBH_VDMA_GRP_DONE to be used as TC2. When set to 10, enables TS2 to drive the DataMover Logical channel. It also selects DM_LCH_END to be used as TC2. When set to 11, enables TS2 to drive the DataMover Logical channel. It also selects SBH_VDMA_GRP_DONE to be used as TC2.
  [25:24] SBH_TS2_GEN — This bit configures the TS2 generation logic. When set to 00, selects the NewTask signal to trigger the task. When set to 01, selects the Counter output NT@cnt to trigger the task. When set to 10, selects the Task Completion TC1 to trigger the task. When set to 11, selects the Task Completion TC1@cnt to trigger the task.
  [23:22] SBH_TS1_SEL — This bit configures the Task Start TS1 destination and selects the Task Completion TC1 source. When set to 00, enables TS1 to drive the Interrupt signal to CPU. It also selects SBH_SOFT_TC to be used as TC1. When set to 01, enables TS1 to drive the VDMA Group Start signal. It also selects SBH_VDMA_GRP_DONE to be used as TC1. When set to 10, enables TS1 to drive the DataMover Logical channel. It also selects DM_LCH_END to be used as TC1. When set to 11, enables TS1 to drive the DataMover Logical channel. It also selects SBH_VDMA_GRP_DONE to be used as TC1.
  [21:20] SBH_TS1_GEN — This bit configures the TS1 generation logic. When set to 0, selects the NewTask (NT) signal to trigger the task. When Set to 1, selects the Counter output NT@cnt to trigger the task. When Set to 2, selects the Counter output NT@~cnt to trigger the task. When Set to 3, selects the Counter output NT@Mcnt to trigger the task.
  [13] SBH_TS2_ENABLE — When set to 1, enables Task Start 2 (SBH_TS1_ENABLE must also be set).
  [12] SBH_TS1_ENABLE — When set to 1, enable Task Start 1. When cleared to 0, keeps the task module in disabled state. Note that transition of 1 to 0 on this bit does not guarantee immediate disable of this module as it would still wait for completion of the trigerred task.
  [11:0] SBH_SL2BC_ENABLE — Enables the corresponding SL2BC to be enabled to generate the New Task Trigger. When multiple bits are set, the corresponding enabled SL2BC Ready signal is ANDed to generate New Task Trigger. This would also enable the Task End notification to be broadcast to the enabled SL2BCs. The bit assignment is as follows 0 : PSL2BC0 1 : PSL2BC1 2 : PSL2BC2 3 : PSL2BC3 4 : PSL2BC4 5 : PSL2BC5 6 : CSL2BC0 7 : CSL2BC1 8 : CSL2BC2 9 : CSL2BC3 10: CSL2BC4 11: CSL2BC5
{0x224+0x10*i} __ALL___SBH_TASK_MODULE_CNT{i} access per field (i=0..3) — Specifies the Counter value that is used to trigerring the Task Module{i}.
  [15:0] SBH_CNT rw — Specifies the Counter value that is used to trigerring the Task Module. For example, To Task Start on every 4th trigger, value 3 should be configured here. Read will return the N-counter's current value.
{0x228+0x10*i} __ALL___SBH_TASK_MODULE_MCNT{i} access per field (i=0..3) — Specifies the M Counter value that is used to trigerring the Task Module{i}.
  [17:0] SBH_MCNT rw — Specifies the Counter value that is used to trigerring the Task Module. For example, To Task Start on every 4th trigger, value 3 should be configured here. Read will return the M-counter's current value.
{0x22C+0x10*i} __ALL___SBH_STATUS_GID_TM{i} access per field (i=0..3) — SBH Task Module status & Vdma Group ID register.
  [9] TS2_STATE ro — 1 : Task Started. 0 : Task completed/not started.
  [8] TS1_STATE ro — 1 : Task Started. 0 : Task completed/not started.
  [7:0] GID rw — Specifies the VDMA Group IDs that needs to be monitored for SBH task modules.
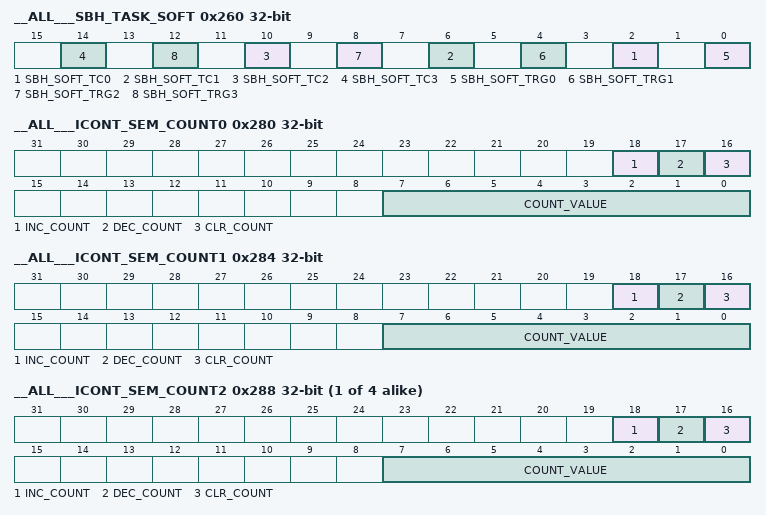
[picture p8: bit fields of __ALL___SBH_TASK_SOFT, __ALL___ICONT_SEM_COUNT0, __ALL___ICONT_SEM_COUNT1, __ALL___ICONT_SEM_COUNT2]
0x260 __ALL___SBH_TASK_SOFT — This register allows SW to generate SOFT trigger to the Task Module and/or task completion to the task module. While the task trigger is always enabled, the Task completion should be selected to be used.
  [4n+2] SBH_SOFT_TC{n} (n=0..3) — When set to 1, generates Soft task completion to Task Module {n}. This bit is auto cleared.
  [4n] SBH_SOFT_TRG{n} (n=0..3) — When set to 1, generates Soft trigger to Task Module {n}. This bit is auto cleared. This trigger would be considered only when the task module is ready to accept the trigger. Setting this bit will be ignored, when the task module is in trigerred state and waiting for completion.
0x280 __ALL___ICONT_SEM_COUNT0 access per field — General purpose counter for SW use. SEM_COUNT0_NZ event will be set whenever the counter value is non-zero. Typically used for semaphore between CPUs, HWA via interrupt and/or events or polling.
  [18] INC_COUNT rw — This bit when set will increment the contents of the counter. This bit is autocleared. Note that SW write to this register should have only one of the 3 control bit set. (Note: The value will be updated in next cycle)
  [17] DEC_COUNT rw — This bit when set will decrement the contents of the counter. This bit is autocleared. Note that SW write to this register should have only one of the 3 control bit set. (Note: The value will be updated in next cycle)
  [16] CLR_COUNT rw — This bit when set will clear the contents of the counter. This bit is autocleared. Note that SW write to this register should have only one of the 3 control bit set. (Note: The value will be updated in next cycle)
  [7:0] COUNT_VALUE ro — Provides the current value of the counter. Counter value if updated based on the following SW writes 1) Clears the count value when CLR_COUNT bitfield is set to 1. 2) Decrements by 1 till it reaches 0 when DEC_COUNT bitfield is set to 1. 3) Increments by 1 till it reaches all-ones count when INC_COUNT bitfield is set to 1.
0x284 __ALL___ICONT_SEM_COUNT1 access per field — General purpose counter for SW use. SEM_COUNT0_NZ event will be set whenever the counter value is non-zero. Typically used for semaphore between CPUs, HWA via interrupt and/or events or polling.
  [18] INC_COUNT rw — This bit when set will increment the contents of the counter. This bit is autocleared. Note that SW write to this register should have only one of the 3 control bit set. (Note: The value will be updated in next cycle)
  [17] DEC_COUNT rw — This bit when set will Decrement the contents of the counter. This bit is autocleared. Note that SW write to this register should have only one of the 3 control bit set. (Note: The value will be updated in next cycle)
  [16] CLR_COUNT rw — This bit when set will clear the contents of the counter. This bit is autocleared. Note that SW write to this register should have only one of the 3 control bit set. (Note: The value will be updated in next cycle)
  [7:0] COUNT_VALUE ro — Provides the current value of the counter. Counter value if updated based on the following SW writes 1) Clears the count value when CLR_COUNT bitfield is set to 1. 2) Decrements by 1 till it reaches 0 when DEC_COUNT bitfield is set to 1. 3) Increments by 1 till it reaches all-ones count when INC_COUNT bitfield is set to 1.
{0x280+4i} __ALL___ICONT_SEM_COUNT{i} access per field (i=2..5) — General purpose counter for SW use. SEM_COUNT{i}_NZ event will be set whenever the counter value is non-zero. Typically used for semaphore between CPUs, HWA via interrupt and/or events or polling.
  fields as __ALL___ICONT_SEM_COUNT0
{0x2A0+0x10*i} __ALL___DM_SOURCEADD_{i} (i=0..3)
  [31:0] Src_Addr
0x2A4 __ALL___DM_DESTADD_0
  [31:0] DST_ADDR — Destination Address
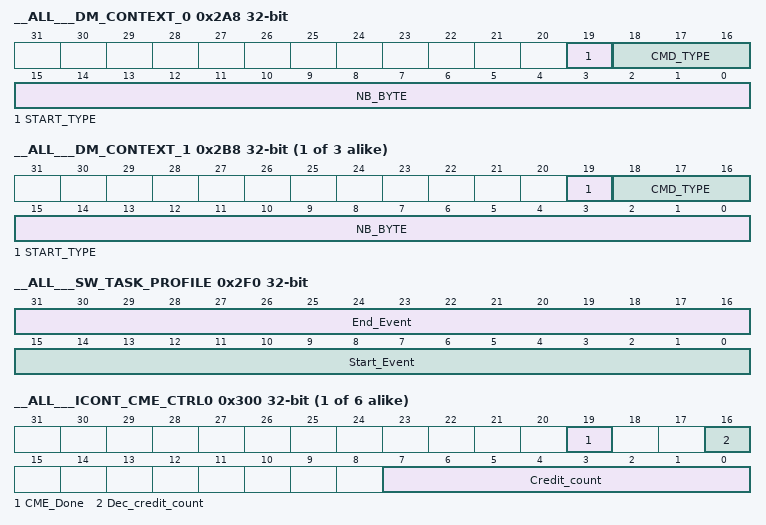
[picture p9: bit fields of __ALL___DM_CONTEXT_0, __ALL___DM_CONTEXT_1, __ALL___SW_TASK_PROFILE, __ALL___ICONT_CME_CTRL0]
0x2A8 __ALL___DM_CONTEXT_0 — A new DM transfer can be scheduled only if this register has been written by SW.
  [19] START_TYPE — 0x0: Transfer is scheduled immediately on write to this register. 0x1: Transfer is scheduled on receiving Logical channel Start notification from SBH.
  [18:16] CMD_TYPE — Type of Transfer 0x0: Transfer from SL2 to DTCM 0x1: Transfer from SL2 to ITCM 0x2: Transfer from DTCM to transversal port to VDMA 0x3: Transfer from SL2 to transversal port to VDMA 0x4: Transfer from DTCM to SL2 0x5: Reserved 0x6: Reserved 0x7: Reserved
  [15:0] NB_BYTE — Number of bytes to transfer (must be a multiple of 128bits)
0x2AC __ALL___DM_STATUS_0 ro — DataMover Status register.
  [1:0] STATUS — 0x00 : Logical channel is in IDLE/Transfer complete state. Descriptor can be programmed. 0x01 : Logical channel is in waiting for Task Start notification from SBH. 0x10 : Logical channel is either queued for transfer or transfer is ongoing. 0x11 : Reserved.
{0x2A4+0x10*i} __ALL___DM_DESTADD_{i} (i=1..3)
  [31:0] Dest_Addr
{0x2A8+0x10*i} __ALL___DM_CONTEXT_{i} (i=1..3)
  fields as __ALL___DM_CONTEXT_0
{0x2AC+0x10*i} __ALL___DM_STATUS_{i} ro (i=1..3)
  fields as __ALL___DM_STATUS_0
0x2F0 __ALL___SW_TASK_PROFILE — This register enables debug/profiling of upto 16 SW task's Start & End events.
  [31:16] End_Event — Set to 1 to send End event notification.
  [15:0] Start_Event — Set to 1 to send Start event notification.
0x2F4 __ALL___WDT_CTRL access per field — WatchDog Timer Control register
  [0] wdt_enable rw — Enables WatchDogTimer to downcount and to generate interrupt when it reaches 0. Transition from low to high state of this bit, preloads the watchdog timer with the contents of WDT_PRELOAD. The WatchDogTimer will downcount subsequently. On reaching 0, it will generate an interrupt. Disabling WatchDogTimer will clear the interrupt.
0x2F8 __ALL___WDT_PRELOAD reset 0xFFFFFFFF — WatchDogTimer preload value. Contents of this register is loaded into the timer on low to high transition of WDT_ENABLE register bit.
0x2FC __ALL___WDT_COUNT ro — Current value of the WatchDogTimer.
{0x300+4i} __ALL___ICONT_CME_CTRL{i} access per field (i=0..5) — Provides read access to CME credits received count. Provides write access to assert po_cme_done signal. Provides write access to decrement the credit counter.
  [19] CME_Done rw — Write 1 to assert the PO_CME_DONE interface. HW will hold the PO_CME_DONE high for 4 clock cycles and then de-assert it. This bitfield is cleared by HW when PO_CME_DONE is de-asserted.
  [16] Dec_credit_count rw — Write 1 to decrement the credit counter by one. Writing 0 has no effect. This bit is autocleared. (Note: The value will be updated in next cycle)
  [7:0] Credit_count ro
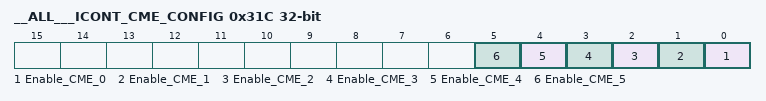
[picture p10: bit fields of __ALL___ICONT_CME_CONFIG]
0x31C __ALL___ICONT_CME_CONFIG — Credit Management Engine config. This register enables (when set to 1) the counters, interrupts & interface associated to CME.
  [n] Enable_CME_{n} (n=0..5) — Enables Pi_cme_start_{n}, Po_cme_done_{n}, ICONT_CME_CTRL{n} and connects the interrupt to local intc interrupt map.
